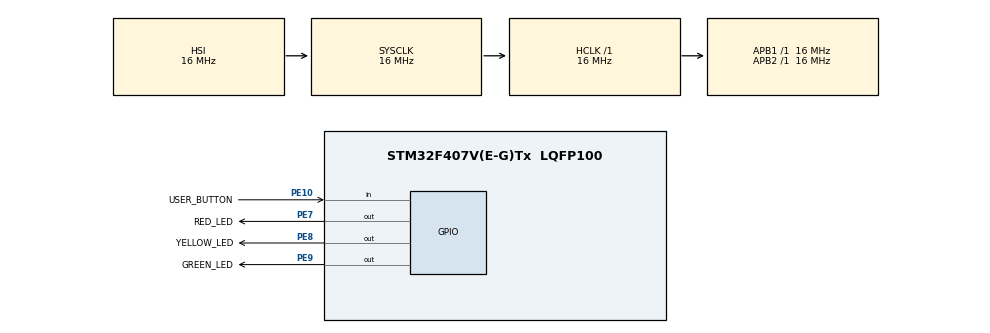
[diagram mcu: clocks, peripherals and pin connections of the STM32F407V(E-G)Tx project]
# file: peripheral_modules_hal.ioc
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Mcu.Family=STM32F4
Mcu.Name=STM32F407V(E-G)Tx
Mcu.Package=LQFP100
NVIC.PriorityGroup=NVIC_PRIORITYGROUP_4
PA13.Mode=Serial_Wire
PA13.Signal=SYS_JTMS-SWDIO
PA14.Mode=Serial_Wire
PA14.Signal=SYS_JTCK-SWCLK
PE10.GPIO_Label=USER_BUTTON
PE10.GPIO_PuPd=GPIO_PULLUP
PE10.Signal=GPIO_Input
PE7.GPIO_Label=RED_LED
PE7.Signal=GPIO_Output
PE8.GPIO_Label=YELLOW_LED
PE8.Signal=GPIO_Output
PE9.GPIO_Label=GREEN_LED
PE9.Signal=GPIO_Output
ProjectManager.HeapSize=0x200
ProjectManager.StackSize=0x400
ProjectManager.TargetToolchain=STM32CubeIDE
RCC.AHBFreq_Value=16000000
RCC.APB1Freq_Value=16000000
RCC.APB2Freq_Value=16000000
RCC.CortexFreq_Value=16000000
RCC.HSE_VALUE=25000000
RCC.HSI_VALUE=16000000
RCC.LSE_VALUE=32768
RCC.SYSCLKFreq_VALUE=16000000
RCC.VCOOutputFreq_Value=192000000
board=custom

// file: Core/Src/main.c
/* USER CODE BEGIN Header */
/**
  ******************************************************************************
  * @file           : main.c
  * @author         : Pedro Valle-Cruz
  * @brief          : Toggle an LED once per debounced press using HAL modules.
  ******************************************************************************
  * @attention
  *
  * Copyright (c) 2026 STMicroelectronics.
  * All rights reserved.
  *
  * This software is licensed under terms that can be found in the LICENSE file
  * in the root directory of this software component.
  * If no LICENSE file comes with this software, it is provided AS-IS.
  *
  ******************************************************************************
  */
/* USER CODE END Header */

#include "main.h"
#include "gpio.h"

/* USER CODE BEGIN Includes */
#include "led.h"
#include "button.h"

/* USER CODE END Includes */

void SystemClock_Config(void);

int main(void)
{

  HAL_Init();

  SystemClock_Config();

  MX_GPIO_Init();
  /* USER CODE BEGIN 2 */
  button_init();
  led_init(7U);
  /* USER CODE END 2 */

  while (1)
  {

    /* USER CODE BEGIN 3 */
    /* One time snapshot and one event check per polling iteration. */
    uint32_t now = HAL_GetTick();
    if (button_update(now) == 1) {
      led_toggle(7U);
    }
  }
  /* USER CODE END 3 */
}

/* Nominal 16 MHz HSI with undivided AHB/APB clocks. */
void SystemClock_Config(void)
{
  RCC_OscInitTypeDef RCC_OscInitStruct = {0};
  RCC_ClkInitTypeDef RCC_ClkInitStruct = {0};

  __HAL_RCC_PWR_CLK_ENABLE();
  __HAL_PWR_VOLTAGESCALING_CONFIG(PWR_REGULATOR_VOLTAGE_SCALE1);

  RCC_OscInitStruct.OscillatorType = RCC_OSCILLATORTYPE_HSI;
  RCC_OscInitStruct.HSIState = RCC_HSI_ON;
  RCC_OscInitStruct.HSICalibrationValue = RCC_HSICALIBRATION_DEFAULT;
  RCC_OscInitStruct.PLL.PLLState = RCC_PLL_NONE;
  if (HAL_RCC_OscConfig(&RCC_OscInitStruct) != HAL_OK)
  {
    Error_Handler();
  }

  RCC_ClkInitStruct.ClockType = RCC_CLOCKTYPE_HCLK|RCC_CLOCKTYPE_SYSCLK
                              |RCC_CLOCKTYPE_PCLK1|RCC_CLOCKTYPE_PCLK2;
  RCC_ClkInitStruct.SYSCLKSource = RCC_SYSCLKSOURCE_HSI;
  RCC_ClkInitStruct.AHBCLKDivider = RCC_SYSCLK_DIV1;
  RCC_ClkInitStruct.APB1CLKDivider = RCC_HCLK_DIV1;
  RCC_ClkInitStruct.APB2CLKDivider = RCC_HCLK_DIV1;

  if (HAL_RCC_ClockConfig(&RCC_ClkInitStruct, FLASH_LATENCY_0) != HAL_OK)
  {
    Error_Handler();
  }
}

void Error_Handler(void)
{
  __disable_irq();
  while (1)
  {
  }
}
